# CBASS_RT_DATA0_QOS register map
Vendor: Texas Instruments
Peripheral module from a debugger description file (folder J722S).
Registers are 32-bit, read-write, reset 0x0 unless marked. A register's access mark holds for its fields unless they carry their own. Offsets are as the file gives them; lines under a group give offsets from that group; [hi:lo] are bit positions; {n}, {i} and the like mark numbered series; 'fields as' and 'values as' point back to an identical list; <NAME> marks a mode.

## CBASS_RT_DATA0_QOS
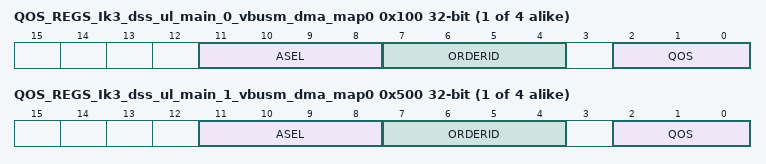
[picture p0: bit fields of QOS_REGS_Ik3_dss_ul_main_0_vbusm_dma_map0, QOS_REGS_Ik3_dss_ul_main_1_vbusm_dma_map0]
{0x100+4i} QOS_REGS_Ik3_dss_ul_main_0_vbusm_dma_map{i} (i=0..3) — The Map Register defines the fields for the initiator Ik3_dss_ul_main_0.vbusm_dma per channel.
  [11:8] ASEL — asel signal for channel N. 0 = SOC address. 1-15 = peripheral address.
  [7:4] ORDERID — orderid signal for channel N.
  [2:0] QOS — qos signal for channel N.
{0x500+4i} QOS_REGS_Ik3_dss_ul_main_1_vbusm_dma_map{i} (i=0..3) — The Map Register defines the fields for the initiator Ik3_dss_ul_main_1.vbusm_dma per channel.
  fields as QOS_REGS_Ik3_dss_ul_main_0_vbusm_dma_map0
